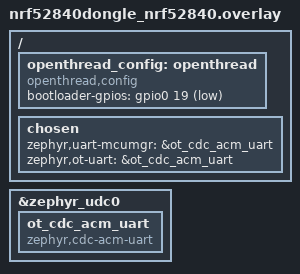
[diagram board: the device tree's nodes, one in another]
/* Copyright (c) 2024 Nordic Semiconductor ASA
 *
 * SPDX-License-Identifier: LicenseRef-Nordic-5-Clause
 */

/ {
	/*
	 * nRF52840 dongle has pin P0.19 connected to reset. By setting it
	 * in `GPIO_OUTPUT_ACTIVE` mode, reset is pulled to GND,
	 * which results in device rebooting without skipping the bootloader.
	 * openthread_config node enables doing so using `reset bootloader` command.
	 */
	openthread_config: openthread {
		compatible = "openthread,config";
		bootloader-gpios = <&gpio0 19 GPIO_ACTIVE_LOW>;
	};

	chosen {
		/*
		 * The USB CDC ACM serial backend only registers multiple instances
		 * for console, shell, and mcumgr chosen UARTs. Reuse the mcumgr slot
		 * so the OT transport gets its own CDC ACM function.
		 */
		zephyr,uart-mcumgr = &ot_cdc_acm_uart;
		/* Keep OT Spinel traffic off the board console CDC ACM port. */
		zephyr,ot-uart = &ot_cdc_acm_uart;
	};
};

&zephyr_udc0 {
	ot_cdc_acm_uart: ot_cdc_acm_uart {
		compatible = "zephyr,cdc-acm-uart";
	};
};
